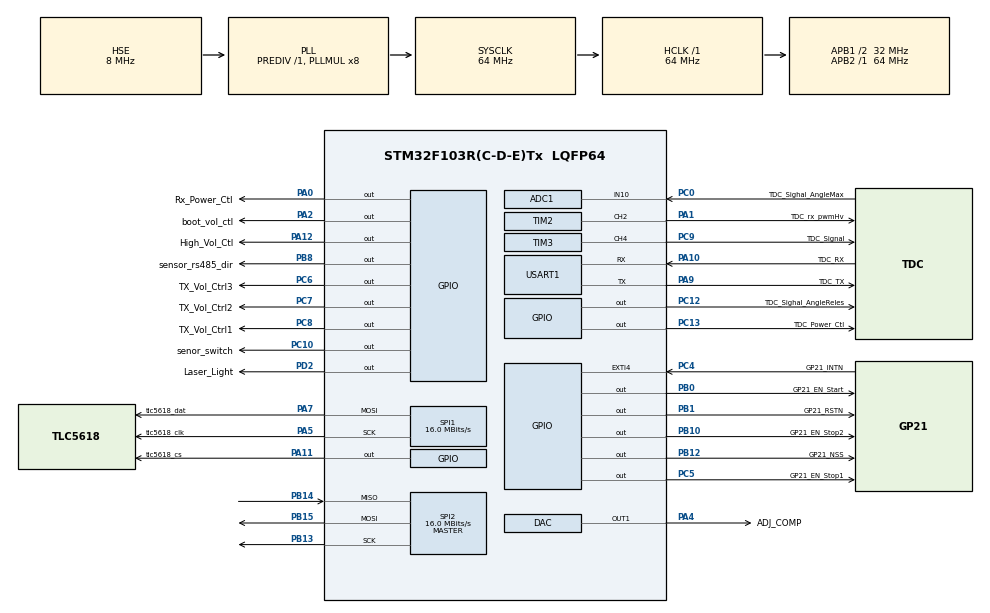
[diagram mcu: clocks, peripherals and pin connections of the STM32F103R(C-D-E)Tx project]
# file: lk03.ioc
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ADC1.Channel-0\#ChannelRegularConversion=ADC_CHANNEL_10
ADC1.ContinuousConvMode=ENABLE
ADC1.DataAlign=ADC_DATAALIGN_RIGHT
ADC1.DiscontinuousConvMode=DISABLE
ADC1.EnableAnalogWatchDog=false
ADC1.EnableRegularConversion=ENABLE
ADC1.ExternalTrigConv=ADC_SOFTWARE_START
ADC1.InjNumberOfConversion=0
ADC1.NbrOfConversion=1
ADC1.NbrOfConversionFlag=1
ADC1.Rank-0\#ChannelRegularConversion=1
ADC1.SamplingTime-0\#ChannelRegularConversion=ADC_SAMPLETIME_1CYCLE_5
ADC1.ScanConvMode=ADC_SCAN_DISABLE
ADC1.master=1
Dma.ADC1.0.Direction=DMA_PERIPH_TO_MEMORY
Dma.ADC1.0.Instance=DMA1_Channel1
Dma.ADC1.0.MemDataAlignment=DMA_MDATAALIGN_HALFWORD
Dma.ADC1.0.MemInc=DMA_MINC_ENABLE
Dma.ADC1.0.Mode=DMA_NORMAL
Dma.ADC1.0.PeriphDataAlignment=DMA_PDATAALIGN_HALFWORD
Dma.ADC1.0.PeriphInc=DMA_PINC_DISABLE
Dma.ADC1.0.Priority=DMA_PRIORITY_LOW
Dma.Request0=ADC1
Dma.Request1=USART1_RX
Dma.USART1_RX.1.Direction=DMA_PERIPH_TO_MEMORY
Dma.USART1_RX.1.Instance=DMA1_Channel5
Dma.USART1_RX.1.MemDataAlignment=DMA_MDATAALIGN_BYTE
Dma.USART1_RX.1.MemInc=DMA_MINC_ENABLE
Dma.USART1_RX.1.Mode=DMA_CIRCULAR
Dma.USART1_RX.1.PeriphDataAlignment=DMA_PDATAALIGN_BYTE
Dma.USART1_RX.1.PeriphInc=DMA_PINC_DISABLE
Dma.USART1_RX.1.Priority=DMA_PRIORITY_LOW
FREERTOS.INCLUDE_vTaskDelayUntil=1
FREERTOS.Tasks01=defaultTask,-3,128,StartDefaultTask,Default,NULL,Dynamic,NULL,NULL
FREERTOS.configMAX_PRIORITIES=10
FREERTOS.configTOTAL_HEAP_SIZE=10000
Mcu.Family=STM32F1
Mcu.Name=STM32F103R(C-D-E)Tx
Mcu.Package=LQFP64
NVIC.ADC1_2_IRQn=true\:6\:0\:true\:false\:true\:true\:true\:true
NVIC.DMA1_Channel1_IRQn=true\:5\:0\:false\:false\:true\:true\:false\:true
NVIC.DMA1_Channel5_IRQn=true\:5\:0\:false\:false\:true\:true\:false\:true
NVIC.EXTI4_IRQn=true\:5\:0\:true\:false\:true\:true\:true\:true
NVIC.PriorityGroup=NVIC_PRIORITYGROUP_4
NVIC.TIM1_UP_IRQn=true\:0\:0\:false\:false\:true\:false\:false\:true
NVIC.TIM3_IRQn=true\:5\:0\:false\:false\:true\:true\:true\:true
NVIC.TIM7_IRQn=true\:5\:0\:false\:false\:true\:true\:true\:true
NVIC.TimeBase=TIM1_UP_IRQn
NVIC.TimeBaseIP=TIM1
NVIC.USART1_IRQn=true\:7\:0\:true\:false\:true\:true\:true\:true
PA0-WKUP.GPIO_Label=Rx_Power_Ctl
PA0-WKUP.GPIO_ModeDefaultOutputPP=GPIO_MODE_OUTPUT_OD
PA0-WKUP.Signal=GPIO_Output
PA1.GPIO_Label=TDC_rx_pwmHv
PA1.Signal=S_TIM2_CH2
PA10.GPIO_Label=TDC_RX
PA10.Mode=Asynchronous
PA10.Signal=USART1_RX
PA11.GPIO_Label=tlc5618_cs
PA11.Signal=GPIO_Output
PA12.GPIO_Label=High_Vol_Ctl
PA12.GPIO_ModeDefaultOutputPP=GPIO_MODE_OUTPUT_OD
PA12.Signal=GPIO_Output
PA13.Mode=Serial_Wire
PA13.Signal=SYS_JTMS-SWDIO
PA14.Mode=Serial_Wire
PA14.Signal=SYS_JTCK-SWCLK
PA2.GPIO_Label=boot_vol_ctl
PA2.GPIO_ModeDefaultOutputPP=GPIO_MODE_OUTPUT_OD
PA2.Signal=GPIO_Output
PA4.GPIO_Label=ADJ_COMP
PA4.Signal=COMP_DAC1_group
PA5.GPIO_Label=tlc5618_clk
PA5.Mode=TX_Only_Simplex_Unidirect_Master
PA5.Signal=SPI1_SCK
PA7.GPIO_Label=tlc5618_dat
PA7.Mode=TX_Only_Simplex_Unidirect_Master
PA7.Signal=SPI1_MOSI
PA9.GPIO_Label=TDC_TX
PA9.Mode=Asynchronous
PA9.Signal=USART1_TX
PB0.GPIO_Label=GP21_EN_Start
PB0.Signal=GPIO_Output
PB1.GPIO_Label=GP21_RSTN
PB1.Signal=GPIO_Output
PB10.GPIO_Label=GP21_EN_Stop2
PB10.Signal=GPIO_Output
PB12.GPIO_Label=GP21_NSS
PB12.PinState=GPIO_PIN_SET
PB12.Signal=GPIO_Output
PB13.Mode=Full_Duplex_Master
PB13.Signal=SPI2_SCK
PB14.Mode=Full_Duplex_Master
PB14.Signal=SPI2_MISO
PB15.Mode=Full_Duplex_Master
PB15.Signal=SPI2_MOSI
PB8.GPIO_Label=sensor_rs485_dir
PB8.Signal=GPIO_Output
PC0.GPIO_Label=TDC_Sighal_AngleMax
PC0.Signal=ADCx_IN10
PC10.GPIO_Label=senor_switch
PC10.GPIO_Speed=GPIO_SPEED_FREQ_HIGH
PC10.Signal=GPIO_Output
PC12.GPIO_Label=TDC_Sighal_AngleReles
PC12.Signal=GPIO_Output
PC13-TAMPER-RTC.GPIO_Label=TDC_Power_Ctl
PC13-TAMPER-RTC.GPIO_ModeDefaultOutputPP=GPIO_MODE_OUTPUT_OD
PC13-TAMPER-RTC.Signal=GPIO_Output
PC4.GPIO_Label=GP21_INTN
PC4.GPIO_ModeDefaultEXTI=GPIO_MODE_IT_FALLING
PC4.GPIO_PuPd=GPIO_PULLUP
PC4.Signal=GPXTI4
PC5.GPIO_Label=GP21_EN_Stop1
PC5.Signal=GPIO_Output
PC6.GPIO_Label=TX_Vol_Ctrl3
PC6.Signal=GPIO_Output
PC7.GPIO_Label=TX_Vol_Ctrl2
PC7.Signal=GPIO_Output
PC8.GPIO_Label=TX_Vol_Ctrl1
PC8.Signal=GPIO_Output
PC9.GPIO_Label=TDC_Signal
PC9.Signal=S_TIM3_CH4
PD0-OSC_IN.Mode=HSE-External-Oscillator
PD0-OSC_IN.Signal=RCC_OSC_IN
PD1-OSC_OUT.Mode=HSE-External-Oscillator
PD1-OSC_OUT.Signal=RCC_OSC_OUT
PD2.GPIO_Label=Laser_Light
PD2.Signal=GPIO_Output
ProjectManager.HeapSize=0x200
ProjectManager.StackSize=0x600
ProjectManager.TargetToolchain=MDK-ARM V5
RCC.ADCPresc=RCC_ADCPCLK2_DIV6
RCC.AHBFreq_Value=64000000
RCC.APB1CLKDivider=RCC_HCLK_DIV2
RCC.APB1Freq_Value=32000000
RCC.APB1TimFreq_Value=64000000
RCC.APB2Freq_Value=64000000
RCC.APB2TimFreq_Value=64000000
RCC.HCLKFreq_Value=64000000
RCC.PLLMUL=RCC_PLL_MUL8
RCC.PLLSourceVirtual=RCC_PLLSOURCE_HSE
RCC.SYSCLKFreq_VALUE=64000000
RCC.SYSCLKSource=RCC_SYSCLKSOURCE_PLLCLK
RCC.USBFreq_Value=64000000
SH.ADCx_IN10.0=ADC1_IN10,IN10
SH.COMP_DAC1_group.0=DAC_OUT1,DAC_OUT1
SH.S_TIM2_CH2.0=TIM2_CH2,PWM Generation2 CH2
SH.S_TIM3_CH4.0=TIM3_CH4,PWM Generation4 CH4
SPI1.BaudRatePrescaler=SPI_BAUDRATEPRESCALER_4
SPI1.CLKPhase=SPI_PHASE_1EDGE
SPI1.CLKPolarity=SPI_POLARITY_HIGH
SPI1.CalculateBaudRate=16.0 MBits/s
SPI1.Direction=SPI_DIRECTION_2LINES
SPI1.Mode=SPI_MODE_MASTER
SPI1.VirtualType=VM_MASTER
SPI2.BaudRatePrescaler=SPI_BAUDRATEPRESCALER_2
SPI2.CLKPhase=SPI_PHASE_2EDGE
SPI2.CalculateBaudRate=16.0 MBits/s
SPI2.Direction=SPI_DIRECTION_2LINES
SPI2.Mode=SPI_MODE_MASTER
SPI2.VirtualType=VM_MASTER
TIM2.Channel-PWM\ Generation2\ CH2=TIM_CHANNEL_2
TIM2.Period=2000
TIM3.Channel-PWM\ Generation4\ CH4=TIM_CHANNEL_4
TIM3.Period=100
TIM3.Prescaler=64
TIM3.Pulse-PWM\ Generation4\ CH4=1
TIM3.TIM_MasterOutputTrigger=TIM_TRGO_UPDATE
TIM7.Period=50
TIM7.Prescaler=64
USART1.VirtualMode=VM_ASYNC
VP_FREERTOS_VS_CMSIS_V1.Mode=CMSIS_V1
VP_SYS_VS_tim1.Mode=TIM1
VP_TIM2_VS_ClockSourceINT.Mode=Internal
VP_TIM3_VS_ClockSourceINT.Mode=Internal
VP_TIM7_VS_ClockSourceINT.Mode=Enable_Timer
board=custom

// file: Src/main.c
/* USER CODE BEGIN Header */
/**
  ******************************************************************************
  * @file           : main.c
  * @brief          : Main program body
  ******************************************************************************
  * This notice applies to any and all portions of this file
  * that are not between comment pairs USER CODE BEGIN and
  * USER CODE END. Other portions of this file, whether
  * inserted by the user or by software development tools
  * are owned by their respective copyright owners.
  *
  * Copyright (c) 2018 STMicroelectronics International N.V.
  * All rights reserved.
  *
  * Redistribution and use in source and binary forms, with or without
  * modification, are permitted, provided that the following conditions are met:
  *
  * 1. Redistribution of source code must retain the above copyright notice,
  *    this list of conditions and the following disclaimer.
  * 2. Redistributions in binary form must reproduce the above copyright notice,
  *    this list of conditions and the following disclaimer in the documentation
  *    and/or other materials provided with the distribution.
  * 3. Neither the name of STMicroelectronics nor the names of other
  *    contributors to this software may be used to endorse or promote products
  *    derived from this software without specific written permission.
  * 4. This software, including modifications and/or derivative works of this
  *    software, must execute solely and exclusively on microcontroller or
  *    microprocessor devices manufactured by or for STMicroelectronics.
  * 5. Redistribution and use of this software other than as permitted under
  *    this license is void and will automatically terminate your rights under
  *    this license.
  *
  * THIS SOFTWARE IS PROVIDED BY STMICROELECTRONICS AND CONTRIBUTORS "AS IS"
  * AND ANY EXPRESS, IMPLIED OR STATUTORY WARRANTIES, INCLUDING, BUT NOT
  * LIMITED TO, THE IMPLIED WARRANTIES OF MERCHANTABILITY, FITNESS FOR A
  * PARTICULAR PURPOSE AND NON-INFRINGEMENT OF THIRD PARTY INTELLECTUAL PROPERTY
  * RIGHTS ARE DISCLAIMED TO THE FULLEST EXTENT PERMITTED BY LAW. IN NO EVENT
  * SHALL STMICROELECTRONICS OR CONTRIBUTORS BE LIABLE FOR ANY DIRECT, INDIRECT,
  * INCIDENTAL, SPECIAL, EXEMPLARY, OR CONSEQUENTIAL DAMAGES (INCLUDING, BUT NOT
  * LIMITED TO, PROCUREMENT OF SUBSTITUTE GOODS OR SERVICES; LOSS OF USE, DATA,
  * OR PROFITS; OR BUSINESS INTERRUPTION) HOWEVER CAUSED AND ON ANY THEORY OF
  * LIABILITY, WHETHER IN CONTRACT, STRICT LIABILITY, OR TORT (INCLUDING
  * NEGLIGENCE OR OTHERWISE) ARISING IN ANY WAY OUT OF THE USE OF THIS SOFTWARE,
  * EVEN IF ADVISED OF THE POSSIBILITY OF SUCH DAMAGE.
  *
  ******************************************************************************
  */
/* USER CODE END Header */

#include "main.h"
#include "cmsis_os.h"
#include "adc.h"
#include "dac.h"
#include "dma.h"
#include "spi.h"
#include "tim.h"
#include "usart.h"
#include "gpio.h"

/* USER CODE BEGIN Includes */
 #include "z_include.h"
 extern SqQueue lk_distQueue;  //ѭ������
/* USER CODE END Includes */

void SystemClock_Config(void);
void MX_FREERTOS_Init(void);

/* USER CODE BEGIN 0 */
extern void lk_dac_init(void);
/* USER CODE END 0 */

int main(void)
{

  /* MCU Configuration--------------------------------------------------------*/

  /* Reset of all peripherals, Initializes the Flash interface and the Systick. */
  HAL_Init();

  /* Configure the system clock */
  SystemClock_Config();

  /* Initialize all configured peripherals */
  MX_GPIO_Init();
  MX_DMA_Init();
  MX_TIM2_Init();
  MX_TIM3_Init();
  MX_ADC1_Init();
  MX_USART1_UART_Init();
  MX_SPI1_Init();
  MX_SPI2_Init();
  MX_DAC_Init();
  MX_TIM7_Init();
  /* USER CODE BEGIN 2 */
  lk_dac_init();
  /* USER CODE END 2 */

  /* Call init function for freertos objects (in freertos.c) */
  MX_FREERTOS_Init();

  /* Start scheduler */
  osKernelStart();

  /* We should never get here as control is now taken by the scheduler */

  /* Infinite loop */
  while (1)
  {

  }
}

void SystemClock_Config(void)
{
  RCC_OscInitTypeDef RCC_OscInitStruct = {0};
  RCC_ClkInitTypeDef RCC_ClkInitStruct = {0};
  RCC_PeriphCLKInitTypeDef PeriphClkInit = {0};

  /** Initializes the CPU, AHB and APB busses clocks
  */
  RCC_OscInitStruct.OscillatorType = RCC_OSCILLATORTYPE_HSE;
  RCC_OscInitStruct.HSEState = RCC_HSE_ON;
  RCC_OscInitStruct.HSEPredivValue = RCC_HSE_PREDIV_DIV1;
  RCC_OscInitStruct.HSIState = RCC_HSI_ON;
  RCC_OscInitStruct.PLL.PLLState = RCC_PLL_ON;
  RCC_OscInitStruct.PLL.PLLSource = RCC_PLLSOURCE_HSE;
  RCC_OscInitStruct.PLL.PLLMUL = RCC_PLL_MUL8;
  if (HAL_RCC_OscConfig(&RCC_OscInitStruct) != HAL_OK)
  {
    Error_Handler();
  }
  /** Initializes the CPU, AHB and APB busses clocks
  */
  RCC_ClkInitStruct.ClockType = RCC_CLOCKTYPE_HCLK|RCC_CLOCKTYPE_SYSCLK
                              |RCC_CLOCKTYPE_PCLK1|RCC_CLOCKTYPE_PCLK2;
  RCC_ClkInitStruct.SYSCLKSource = RCC_SYSCLKSOURCE_PLLCLK;
  RCC_ClkInitStruct.AHBCLKDivider = RCC_SYSCLK_DIV1;
  RCC_ClkInitStruct.APB1CLKDivider = RCC_HCLK_DIV2;
  RCC_ClkInitStruct.APB2CLKDivider = RCC_HCLK_DIV1;

  if (HAL_RCC_ClockConfig(&RCC_ClkInitStruct, FLASH_LATENCY_2) != HAL_OK)
  {
    Error_Handler();
  }
  PeriphClkInit.PeriphClockSelection = RCC_PERIPHCLK_ADC;
  PeriphClkInit.AdcClockSelection = RCC_ADCPCLK2_DIV6;
  if (HAL_RCCEx_PeriphCLKConfig(&PeriphClkInit) != HAL_OK)
  {
    Error_Handler();
  }
}

void HAL_TIM_PeriodElapsedCallback(TIM_HandleTypeDef *htim)
{
  if (htim->Instance == TIM1) {
    HAL_IncTick();
  }
}

void Error_Handler(void)
{
}

/************************ (C) COPYRIGHT STMicroelectronics *****END OF FILE****/

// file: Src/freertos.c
/* USER CODE BEGIN Header */
/**
  ******************************************************************************
  * File Name          : freertos.c
  * Description        : Code for freertos applications
  ******************************************************************************
  * This notice applies to any and all portions of this file
  * that are not between comment pairs USER CODE BEGIN and
  * USER CODE END. Other portions of this file, whether
  * inserted by the user or by software development tools
  * are owned by their respective copyright owners.
  *
  * Copyright (c) 2018 STMicroelectronics International N.V.
  * All rights reserved.
  *
  * Redistribution and use in source and binary forms, with or without
  * modification, are permitted, provided that the following conditions are met:
  *
  * 1. Redistribution of source code must retain the above copyright notice,
  *    this list of conditions and the following disclaimer.
  * 2. Redistributions in binary form must reproduce the above copyright notice,
  *    this list of conditions and the following disclaimer in the documentation
  *    and/or other materials provided with the distribution.
  * 3. Neither the name of STMicroelectronics nor the names of other
  *    contributors to this software may be used to endorse or promote products
  *    derived from this software without specific written permission.
  * 4. This software, including modifications and/or derivative works of this
  *    software, must execute solely and exclusively on microcontroller or
  *    microprocessor devices manufactured by or for STMicroelectronics.
  * 5. Redistribution and use of this software other than as permitted under
  *    this license is void and will automatically terminate your rights under
  *    this license.
  *
  * THIS SOFTWARE IS PROVIDED BY STMICROELECTRONICS AND CONTRIBUTORS "AS IS"
  * AND ANY EXPRESS, IMPLIED OR STATUTORY WARRANTIES, INCLUDING, BUT NOT
  * LIMITED TO, THE IMPLIED WARRANTIES OF MERCHANTABILITY, FITNESS FOR A
  * PARTICULAR PURPOSE AND NON-INFRINGEMENT OF THIRD PARTY INTELLECTUAL PROPERTY
  * RIGHTS ARE DISCLAIMED TO THE FULLEST EXTENT PERMITTED BY LAW. IN NO EVENT
  * SHALL STMICROELECTRONICS OR CONTRIBUTORS BE LIABLE FOR ANY DIRECT, INDIRECT,
  * INCIDENTAL, SPECIAL, EXEMPLARY, OR CONSEQUENTIAL DAMAGES (INCLUDING, BUT NOT
  * LIMITED TO, PROCUREMENT OF SUBSTITUTE GOODS OR SERVICES; LOSS OF USE, DATA,
  * OR PROFITS; OR BUSINESS INTERRUPTION) HOWEVER CAUSED AND ON ANY THEORY OF
  * LIABILITY, WHETHER IN CONTRACT, STRICT LIABILITY, OR TORT (INCLUDING
  * NEGLIGENCE OR OTHERWISE) ARISING IN ANY WAY OUT OF THE USE OF THIS SOFTWARE,
  * EVEN IF ADVISED OF THE POSSIBILITY OF SUCH DAMAGE.
  *
  ******************************************************************************
  */
/* USER CODE END Header */

#include "FreeRTOS.h"
#include "task.h"
#include "main.h"
#include "cmsis_os.h"

/* USER CODE BEGIN Includes */
#include "z_include.h"
/* USER CODE END Includes */

/* USER CODE BEGIN PTD */
extern void z_tiny_test(void);
uint32_t test_td21=0;
//AGC Control
int16_t pid_resualt=0,ad603_resualt=0;

/* USER CODE END PTD */

osThreadId defaultTaskHandle;

void StartDefaultTask(void const * argument);

void MX_FREERTOS_Init(void); /* (MISRA C 2004 rule 8.1) */

void MX_FREERTOS_Init(void) {

  /* Create the thread(s) */
  /* definition and creation of defaultTask */
  osThreadDef(defaultTask, StartDefaultTask, osPriorityIdle, 0, 128);
  defaultTaskHandle = osThreadCreate(osThread(defaultTask), NULL);

  /* USER CODE BEGIN RTOS_THREADS */
  z_taskCreate();
  /* USER CODE END RTOS_THREADS */

}

void StartDefaultTask(void const * argument)
{

  /* USER CODE BEGIN StartDefaultTask */
	//z_taskCreate();
  /* Infinite loop */
  for(;;)
  {

    osDelay(500);
  }
  /* USER CODE END StartDefaultTask */
}

/************************ (C) COPYRIGHT STMicroelectronics *****END OF FILE****/
